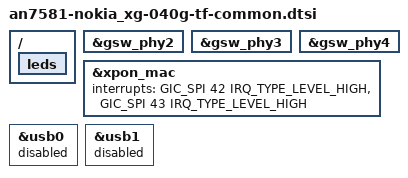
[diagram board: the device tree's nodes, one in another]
// SPDX-License-Identifier: GPL-2.0-only OR MIT

#include "an7581-nokia_xg-040g-md-common.dtsi"

/ {
	/* The TF panel exposes power, PON, LOS, and network status LEDs. */
	leds {
		/delete-node/ led-4;
		/delete-node/ led-5;
	};

	/delete-node/ regulator-usb1-vbus;
	/delete-node/ regulator-usb2-vbus;
	/delete-node/ usb1-vbus-oc;
	/delete-node/ usb2-vbus-oc;
};

/* The TF internal Gigabit PHY uses phylib polling. */
&gsw_phy2 {
	/delete-property/ interrupts;
};

&gsw_phy3 {
	/delete-property/ interrupts;
};

&gsw_phy4 {
	/delete-property/ interrupts;
};

/* The supply-drop wiring is known for the MD board only. */
&xpon_mac {
	interrupts = <GIC_SPI 42 IRQ_TYPE_LEVEL_HIGH>,
		     <GIC_SPI 43 IRQ_TYPE_LEVEL_HIGH>;
	interrupt-names = "mac", "phy";

	/delete-property/ airoha,dying-gasp-shed-gpios;
};

&usb0 {
	status = "disabled";

	/delete-property/ vusb33-supply;
	/delete-node/ port@1;
};

&usb1 {
	status = "disabled";

	/delete-property/ mediatek,u3p-dis-msk;
	/delete-property/ phys;
	/delete-property/ vusb33-supply;
	/delete-node/ port@1;
};
